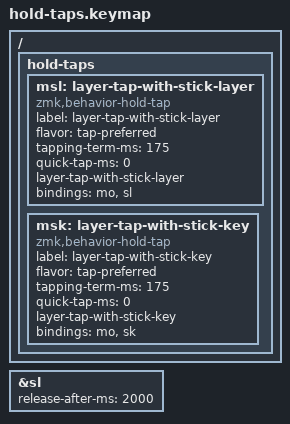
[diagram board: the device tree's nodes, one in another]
/*
*
* Copyright (c) 2022 Rafael Romão
* SPDX-License-Identifier: MIT
*
*/

#include <behaviors.dtsi>
#include <dt-bindings/zmk/keys.h>
#include <dt-bindings/zmk/bt.h>

&sl {
    release-after-ms = <2000>;
};

/ {
    hold-taps {
        msl: layer-tap-with-stick-layer {
            compatible = "zmk,behavior-hold-tap";
            label = "layer-tap-with-stick-layer";
            #binding-cells = <2>;
            flavor = "tap-preferred";
            tapping-term-ms = <175>;
            quick-tap-ms = <0>;
            layer-tap-with-stick-layer;
            bindings = <&mo>, <&sl>;
        };
        msk: layer-tap-with-stick-key {
            compatible = "zmk,behavior-hold-tap";
            label = "layer-tap-with-stick-key";
            #binding-cells = <2>;
            flavor = "tap-preferred";
            tapping-term-ms = <175>;
            quick-tap-ms = <0>;
            layer-tap-with-stick-key;
            bindings = <&mo>, <&sk>;
        };
    };
};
